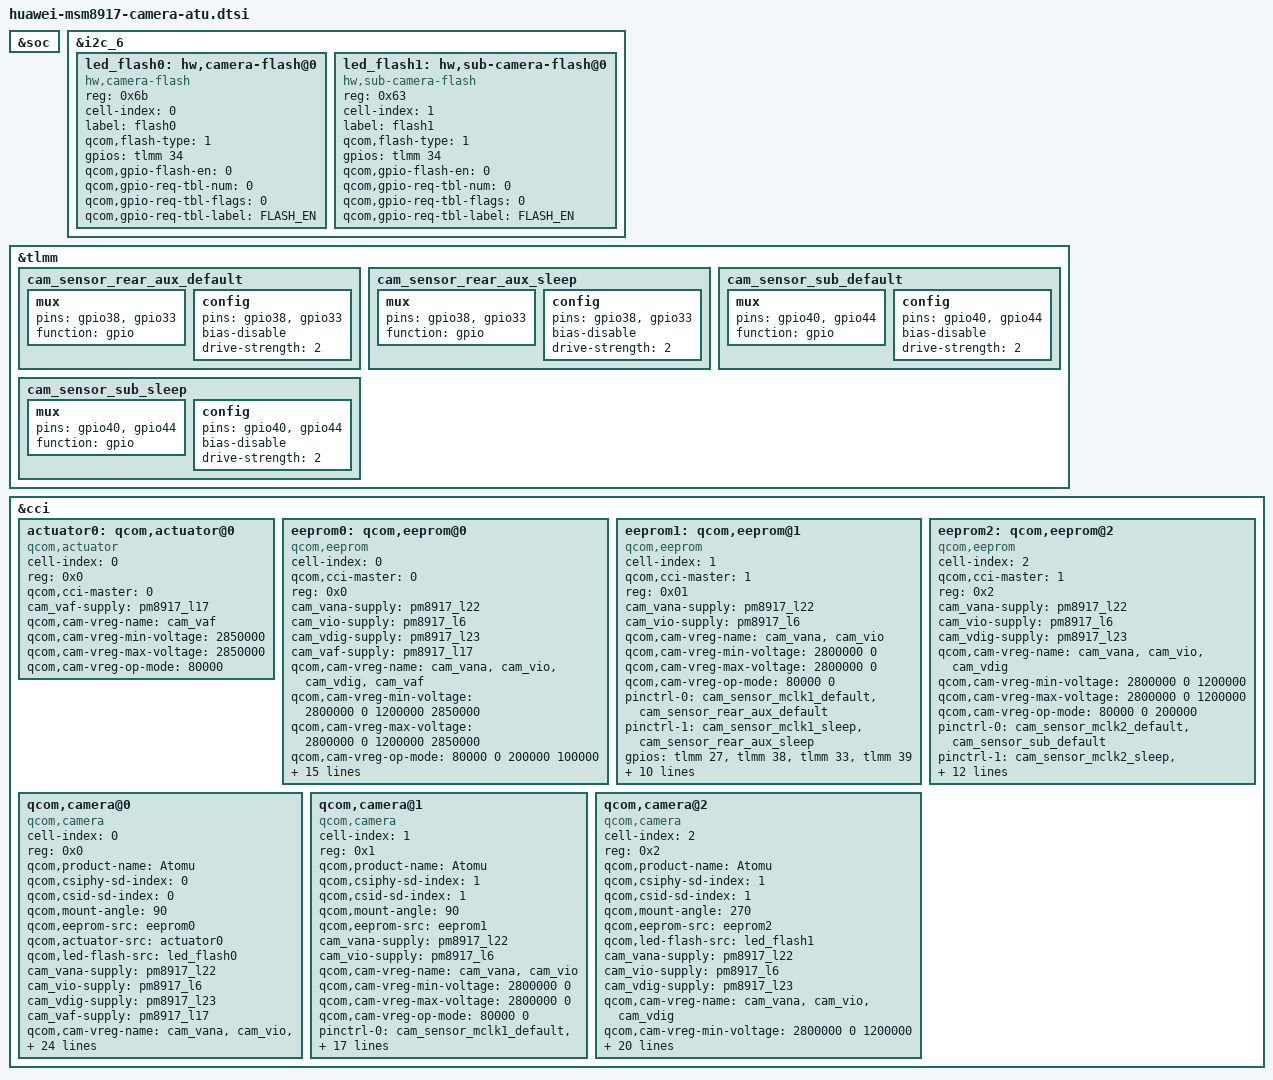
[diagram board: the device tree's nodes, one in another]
/*
 * Copyright (c) 2015-2016, The Linux Foundation. All rights reserved.
 *
 * This program is free software; you can redistribute it and/or modify
 * it under the terms of the GNU General Public License version 2 and
 * only version 2 as published by the Free Software Foundation.
 *
 * This program is distributed in the hope that it will be useful,
 * but WITHOUT ANY WARRANTY; without even the implied warranty of
 * MERCHANTABILITY or FITNESS FOR A PARTICULAR PURPOSE.  See the
 * GNU General Public License for more details.
 */
&soc {
	/delete-node/ qcom,camera-flash;
};

&i2c_6 {
	led_flash0:hw,camera-flash@0 {
		reg = <0x6b>;
		cell-index = <0>;
		compatible = "hw,camera-flash";
		label = "flash0";
		qcom,flash-type = <1>;
		gpios = <&tlmm 34 0>;
		qcom,gpio-flash-en = <0>;
		qcom,gpio-req-tbl-num = <0>;
		qcom,gpio-req-tbl-flags = <0>;
		qcom,gpio-req-tbl-label = "FLASH_EN";
	};

	led_flash1:hw,sub-camera-flash@0 {
		reg = <0x63>;
		cell-index = <1>;
		compatible = "hw,sub-camera-flash";
		label = "flash1";
		qcom,flash-type = <1>;
		gpios = <&tlmm 34 0>;
		qcom,gpio-flash-en = <0>;
		qcom,gpio-req-tbl-num = <0>;
		qcom,gpio-req-tbl-flags = <0>;
		qcom,gpio-req-tbl-label = "FLASH_EN";
	};

};
&tlmm {
	cam_sensor_rear_aux_default: cam_sensor_rear_aux_default {
		/* RESET, STANDBY */
		mux {
			pins = "gpio38","gpio33";
			function = "gpio";
		};

		config {
			pins = "gpio38","gpio33";
			bias-disable; /* No PULL */
			drive-strength = <2>; /* 2 MA */
		};
	};

	cam_sensor_rear_aux_sleep: cam_sensor_rear_aux_sleep {
		/* RESET, STANDBY */
		mux {
			pins = "gpio38","gpio33";
			function = "gpio";
		};

		config {
			pins = "gpio38","gpio33";
			bias-disable; /* No PULL */
			drive-strength = <2>; /* 2 MA */
		};
	};

	cam_sensor_sub_default: cam_sensor_sub_default {
		/* RESET, STANDBY */
		mux {
			pins = "gpio40","gpio44";
			function = "gpio";
		};

		config {
			pins = "gpio40","gpio44";
			bias-disable; /* No PULL */
			drive-strength = <2>; /* 2 MA */
		};
	};

	cam_sensor_sub_sleep: cam_sensor_sub_sleep {
		/* RESET, STANDBY */
		mux {
			pins = "gpio40","gpio44";
			function = "gpio";
		};

		config {
			pins = "gpio40","gpio44";
			bias-disable; /* No PULL */
			drive-strength = <2>; /* 2 MA */
		};
	};
};
&cci {
	actuator0: qcom,actuator@0 {
		cell-index = <0>;
		reg = <0x0>;
		compatible = "qcom,actuator";
		qcom,cci-master = <0>;
		cam_vaf-supply = <&pm8917_l17>;
		qcom,cam-vreg-name = "cam_vaf";
		qcom,cam-vreg-min-voltage = <2850000>;
		qcom,cam-vreg-max-voltage = <2850000>;
		qcom,cam-vreg-op-mode = <80000>;
	};
	eeprom0: qcom,eeprom@0 {
		cell-index = <0>;
		compatible = "qcom,eeprom";
		qcom,cci-master = <0>;
		reg = <0x0>;
		cam_vana-supply = <&pm8917_l22>;
		cam_vio-supply = <&pm8917_l6>;
		cam_vdig-supply = <&pm8917_l23>;
		cam_vaf-supply = <&pm8917_l17>;
		qcom,cam-vreg-name = "cam_vana", "cam_vio", "cam_vdig", "cam_vaf";
		qcom,cam-vreg-min-voltage = <2800000 0 1200000 2850000>;
		qcom,cam-vreg-max-voltage = <2800000 0 1200000 2850000>;
		qcom,cam-vreg-op-mode = <80000 0 200000 100000>;
		pinctrl-names = "cam_default", "cam_suspend";
		pinctrl-0 = <&cam_sensor_mclk0_default &cam_sensor_rear_default>;
		pinctrl-1 = <&cam_sensor_mclk0_sleep &cam_sensor_rear_sleep>;
		gpios = <&tlmm 26 0>,
			<&tlmm 36 0>,
			<&tlmm 35 0>,
			<&tlmm 131 0>;
		qcom,gpio-reset = <1>;
		qcom,gpio-af-pwdm = <2>;
		qcom,gpio-cam-id = <3>;
		qcom,gpio-req-tbl-num = <0 1 2 3>;
		qcom,gpio-req-tbl-flags = <1 0 0 1>;
		qcom,gpio-req-tbl-label = "CAMIF_MCLK0",
			"CAM_RESET0",
			"CAM_AF_PWDM0",
			"CAM_ID0";
		status = "ok";
		clocks = <&clock_gcc clk_mclk0_clk_src>,
			<&clock_gcc clk_gcc_camss_mclk0_clk>;
		clock-names = "cam_src_clk", "cam_clk";
		qcom,clock-rates = <24000000 0>;
	};
	eeprom1: qcom,eeprom@1 {
		cell-index = <1>;
		compatible = "qcom,eeprom";
		qcom,cci-master = <1>;
		reg = <0x01>;
		cam_vana-supply = <&pm8917_l22>;
		cam_vio-supply = <&pm8917_l6>;
		qcom,cam-vreg-name = "cam_vana", "cam_vio";
		qcom,cam-vreg-min-voltage = <2800000 0>;
		qcom,cam-vreg-max-voltage = <2800000 0>;
		qcom,cam-vreg-op-mode = <80000 0>;
		pinctrl-names = "cam_default", "cam_suspend";
		pinctrl-0 = <&cam_sensor_mclk1_default &cam_sensor_rear_aux_default>;
		pinctrl-1 = <&cam_sensor_mclk1_sleep &cam_sensor_rear_aux_sleep>;
		gpios = <&tlmm 27 0>,
			<&tlmm 38 0>,
			<&tlmm 33 0>,
			<&tlmm 39 0>;
		qcom,gpio-reset = <1>;
		qcom,gpio-standby = <2>;
		qcom,gpio-cam-id = <3>;
		qcom,gpio-req-tbl-num = <0 1 2 3>;
		qcom,gpio-req-tbl-flags = <1 0 0 1>;
		qcom,gpio-req-tbl-label = "CAMIF_MCLK1",
			"CAM_RESET1",
			"CAM_STANDBY1",
			"CAM_ID1";
		status = "ok";
		clocks = <&clock_gcc clk_mclk1_clk_src>,
				<&clock_gcc clk_gcc_camss_mclk1_clk>;
		clock-names = "cam_src_clk", "cam_clk";
		qcom,clock-rates = <24000000 0>;
	};
	eeprom2: qcom,eeprom@2 {
		cell-index = <2>;
		compatible = "qcom,eeprom";
		qcom,cci-master = <1>;
		reg = <0x2>;
		cam_vana-supply = <&pm8917_l22>;
		cam_vio-supply = <&pm8917_l6>;
		cam_vdig-supply = <&pm8917_l23>;
		qcom,cam-vreg-name = "cam_vana", "cam_vio", "cam_vdig";
		qcom,cam-vreg-min-voltage = <2800000 0 1200000>;
		qcom,cam-vreg-max-voltage = <2800000 0 1200000>;
		qcom,cam-vreg-op-mode = <80000 0 200000>;
		pinctrl-names = "cam_default", "cam_suspend";
		pinctrl-0 = <&cam_sensor_mclk2_default &cam_sensor_sub_default>;
		pinctrl-1 = <&cam_sensor_mclk2_sleep &cam_sensor_sub_sleep>;
		gpios = <&tlmm 28 0>,
			<&tlmm 40 0>,
			<&tlmm 44 0>,
			<&tlmm 41 0>;
		qcom,gpio-reset = <1>;
		qcom,gpio-standby = <2>;
		qcom,gpio-cam-id = <3>;
		qcom,gpio-req-tbl-num = <0 1 2 3>;
		qcom,gpio-req-tbl-flags = <1 0 0 1>;
		qcom,gpio-req-tbl-label = "CAMIF_MCLK2",
			"CAM_RESET2",
			"CAM_STANDBY2",
			"CAM_ID2";
		status = "ok";
		clocks = <&clock_gcc clk_mclk2_clk_src>,
			<&clock_gcc clk_gcc_camss_mclk2_clk>;
		clock-names = "cam_src_clk", "cam_clk";
		qcom,clock-rates = <24000000 0>;
	};

	qcom,camera@0 { //13M main back
		cell-index = <0>;
		compatible = "qcom,camera";
		reg = <0x0>;
		qcom,product-name = "Atomu";
		qcom,csiphy-sd-index = <0>;
		qcom,csid-sd-index = <0>;
		qcom,mount-angle = <90>;
		qcom,eeprom-src = <&eeprom0>;
		qcom,actuator-src = <&actuator0>;
		qcom,led-flash-src = <&led_flash0>;
		cam_vana-supply = <&pm8917_l22>;
		cam_vio-supply = <&pm8917_l6>;
		cam_vdig-supply = <&pm8917_l23>;
		cam_vaf-supply = <&pm8917_l17>;
		qcom,cam-vreg-name = "cam_vana", "cam_vio", "cam_vdig", "cam_vaf";
		qcom,cam-vreg-min-voltage = <2800000 0 1200000 2850000>;
		qcom,cam-vreg-max-voltage = <2800000 0 1200000 2850000>;
		qcom,cam-vreg-op-mode = <80000 0 200000 100000>;
		pinctrl-names = "cam_default", "cam_suspend";
		pinctrl-0 = <&cam_sensor_mclk0_default &cam_sensor_rear_default>;
		pinctrl-1 = <&cam_sensor_mclk0_sleep &cam_sensor_rear_sleep>;
		gpios = <&tlmm 26 0>,
			<&tlmm 36 0>,
			<&tlmm 35 0>,
			<&tlmm 131 0>;
		qcom,gpio-reset = <1>;
		qcom,gpio-af-pwdm = <2>;
		qcom,gpio-cam-id = <3>;
		qcom,gpio-req-tbl-num = <0 1 2 3>;
		qcom,gpio-req-tbl-flags = <1 0 0 1>;
		qcom,gpio-req-tbl-label = "CAMIF_MCLK0",
			"CAM_RESET0",
			"CAM_AF_PWDM0",
			"CAM_ID0";
		qcom,sensor-position = <0>;
		qcom,sensor-mode = <0>;
		qcom,cci-master = <0>;
		status = "ok";
		clocks = <&clock_gcc clk_mclk0_clk_src>,
				<&clock_gcc clk_gcc_camss_mclk0_clk>;
		clock-names = "cam_src_clk", "cam_clk";
		qcom,clock-rates = <24000000 0>;
	};

	qcom,camera@1 { //Back aux camera
		cell-index = <1>;
		compatible = "qcom,camera";
		reg = <0x1>;
		qcom,product-name = "Atomu";
		qcom,csiphy-sd-index = <1>;
		qcom,csid-sd-index = <1>;
		qcom,mount-angle = <90>;
		qcom,eeprom-src = <&eeprom1>;
		cam_vana-supply = <&pm8917_l22>;
		cam_vio-supply = <&pm8917_l6>;
		qcom,cam-vreg-name = "cam_vana", "cam_vio";
		qcom,cam-vreg-min-voltage = <2800000 0>;
		qcom,cam-vreg-max-voltage = <2800000 0>;
		qcom,cam-vreg-op-mode = <80000 0>;
		pinctrl-names = "cam_default", "cam_suspend";
		pinctrl-0 = <&cam_sensor_mclk1_default &cam_sensor_rear_aux_default>;
		pinctrl-1 = <&cam_sensor_mclk1_sleep &cam_sensor_rear_aux_sleep>;
		gpios = <&tlmm 27 0>,
			<&tlmm 38 0>,
			<&tlmm 33 0>,
			<&tlmm 39 0>;
		qcom,gpio-reset = <1>;
		qcom,gpio-standby = <2>;
		qcom,gpio-cam-id = <3>;
		qcom,gpio-req-tbl-num = <0 1 2 3>;
		qcom,gpio-req-tbl-flags = <1 0 0 1>;
		qcom,gpio-req-tbl-label = "CAMIF_MCLK1",
			"CAM_RESET1",
			"CAM_STANDBY1",
			"CAM_ID1";
		qcom,sensor-position = <0>;
		qcom,sensor-mode = <0>;
		qcom,cci-master = <1>;
		status = "ok";
		clocks = <&clock_gcc clk_mclk1_clk_src>,
				<&clock_gcc clk_gcc_camss_mclk1_clk>;
		clock-names = "cam_src_clk", "cam_clk";
		qcom,clock-rates = <24000000 0>;
	};

	qcom,camera@2 {//5M front
		cell-index = <2>;
		compatible = "qcom,camera";
		reg = <0x2>;
		qcom,product-name = "Atomu";
		qcom,csiphy-sd-index = <1>;
		qcom,csid-sd-index = <1>;
		qcom,mount-angle = <270>;
		qcom,eeprom-src = <&eeprom2>;
		qcom,led-flash-src = <&led_flash1>;
		cam_vana-supply = <&pm8917_l22>;
		cam_vio-supply = <&pm8917_l6>;
		cam_vdig-supply = <&pm8917_l23>;
		qcom,cam-vreg-name = "cam_vana", "cam_vio", "cam_vdig";
		qcom,cam-vreg-min-voltage = <2800000 0 1200000>;
		qcom,cam-vreg-max-voltage = <2800000 0 1200000>;
		qcom,cam-vreg-op-mode = <80000 0 200000>;
		pinctrl-names = "cam_default", "cam_suspend";
		pinctrl-0 = <&cam_sensor_mclk2_default &cam_sensor_sub_default>;
		pinctrl-1 = <&cam_sensor_mclk2_sleep &cam_sensor_sub_sleep>;
		gpios = <&tlmm 28 0>,
			<&tlmm 40 0>,
			<&tlmm 44 0>,
			<&tlmm 41 0>;
		qcom,gpio-reset = <1>;
		qcom,gpio-standby = <2>;
		qcom,gpio-cam-id = <3>;
		qcom,gpio-req-tbl-num = <0 1 2 3>;
		qcom,gpio-req-tbl-flags = <1 0 0 1>;
		qcom,gpio-req-tbl-label = "CAMIF_MCLK2",
			"CAM_RESET2",
			"CAM_STANDBY2",
			"CAM_ID2";
		qcom,sensor-position = <1>;
		qcom,sensor-mode = <0>;
		qcom,cci-master = <1>;
		status = "ok";
		clocks = <&clock_gcc clk_mclk2_clk_src>,
				<&clock_gcc clk_gcc_camss_mclk2_clk>;
		clock-names = "cam_src_clk", "cam_clk";
		qcom,clock-rates = <24000000 0>;
	};
};
